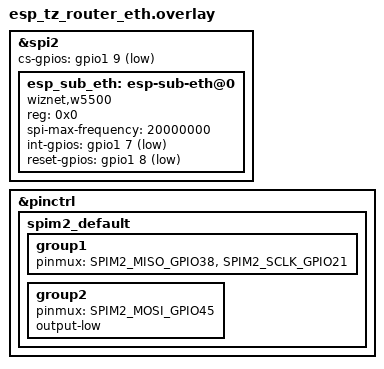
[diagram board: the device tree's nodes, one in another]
/*
 * Copyright (c) 2025 Espressif Systems (Shanghai) Co., Ltd.
 *
 * SPDX-License-Identifier: Apache-2.0
 */

&spi2 {
	status = "okay";
	cs-gpios = <&gpio1 9 GPIO_ACTIVE_LOW>;

	esp_sub_eth: esp-sub-eth@0 {
		compatible = "wiznet,w5500";
		reg = <0x0>;
		spi-max-frequency = <20000000>;
		int-gpios = <&gpio1 7 GPIO_ACTIVE_LOW>;
		reset-gpios = <&gpio1 8 GPIO_ACTIVE_LOW>;
	};
};

&pinctrl {
	spim2_default: spim2_default {
		group1 {
			pinmux = <SPIM2_MISO_GPIO38>,
				 <SPIM2_SCLK_GPIO21>;
		};

		group2 {
			pinmux = <SPIM2_MOSI_GPIO45>;
			output-low;
		};
	};
};
